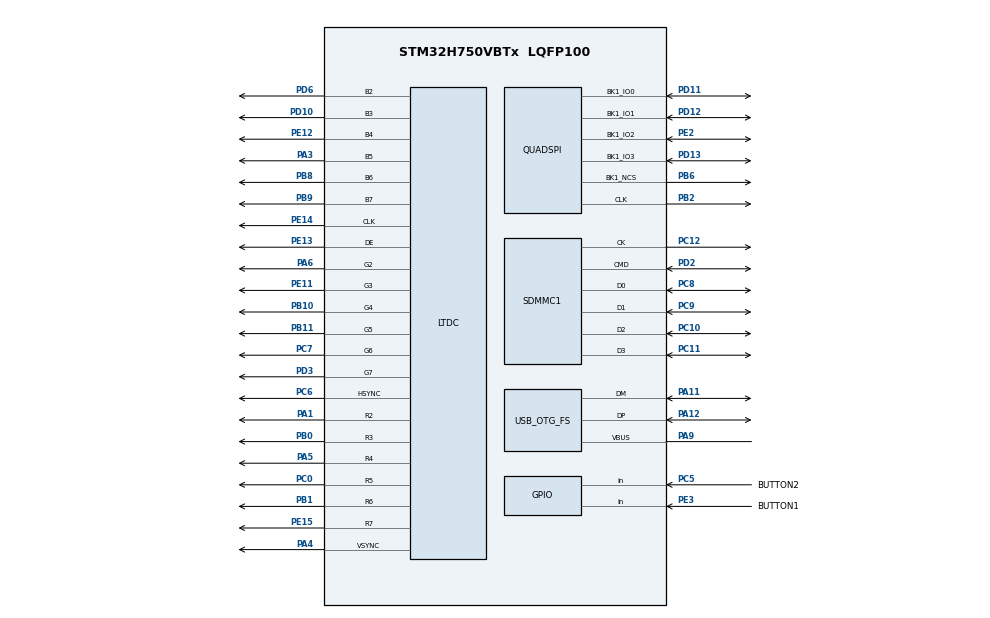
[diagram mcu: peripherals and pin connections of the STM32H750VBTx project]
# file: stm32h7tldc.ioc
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CORTEX_M7.AccessPermission-Cortex_Memory_Protection_Unit_Region0_Settings=MPU_REGION_FULL_ACCESS
CORTEX_M7.BaseAddress-Cortex_Memory_Protection_Unit_Region0_Settings=0x90000000
CORTEX_M7.CPU_DCache=Disabled
CORTEX_M7.CPU_ICache=Enabled
CORTEX_M7.DisableExec-Cortex_Memory_Protection_Unit_Region0_Settings=MPU_INSTRUCTION_ACCESS_DISABLE
CORTEX_M7.Enable-Cortex_Memory_Protection_Unit_Region0_Settings=MPU_REGION_ENABLE
CORTEX_M7.IsBufferable-Cortex_Memory_Protection_Unit_Region0_Settings=MPU_ACCESS_BUFFERABLE
CORTEX_M7.IsCacheable-Cortex_Memory_Protection_Unit_Region0_Settings=MPU_ACCESS_CACHEABLE
CORTEX_M7.MPU_Control=MPU_HFNMI_PRIVDEF
CORTEX_M7.Size-Cortex_Memory_Protection_Unit_Region0_Settings=MPU_REGION_SIZE_8MB
FATFS._FS_EXFAT=1
FATFS._FS_MINIMIZE=1
FATFS._LFN_UNICODE=1
FATFS._STRF_ENCODE=0
FATFS._USE_LFN=1
FATFS._USE_MKFS=0
JPEG.USE_JPEG_DECODER=0
JPEG.USE_JPEG_ENCODER=1
LTDC.ActiveH=480
LTDC.ActiveW=848
LTDC.Alpha0_L0=0xff
LTDC.Alpha_L0=0xff
LTDC.BlendingFactor2_L0=LTDC_BLENDING_FACTOR2_PAxCA
LTDC.Blue_L0=0
LTDC.DEPolarity=LTDC_DEPOLARITY_AL
LTDC.FBStartAdress_L0=(uint32_t)VideoRam
LTDC.Green_L0=0xff
LTDC.HBP=112
LTDC.HFP=16
LTDC.HSPolarity=LTDC_HSPOLARITY_AH
LTDC.HSync=112
LTDC.ImageHeight_L0=480
LTDC.ImageWidth_L0=848
LTDC.Layers=0
LTDC.PCPolarity=LTDC_PCPOLARITY_IIPC
LTDC.PixelFormat_L0=LTDC_PIXEL_FORMAT_L8
LTDC.Red_L0=0
LTDC.VBP=23
LTDC.VFP=6
LTDC.VSPolarity=LTDC_VSPOLARITY_AH
LTDC.VSync=8
LTDC.WindowX1_L0=847
LTDC.WindowY1_L0=479
Mcu.Family=STM32H7
Mcu.Name=STM32H750VBTx
Mcu.Package=LQFP100
Mdma.MDMA_Channel0.JPEG_INFIFO_TH.0.BlockCount=0
Mdma.MDMA_Channel0.JPEG_INFIFO_TH.0.BlockDataLength=0
Mdma.MDMA_Channel0.JPEG_INFIFO_TH.0.BufferTransferLength=32
Mdma.MDMA_Channel0.JPEG_INFIFO_TH.0.CircularMode=MDMA_LINEAR_LIST
Mdma.MDMA_Channel0.JPEG_INFIFO_TH.0.DataAlignment=MDMA_DATAALIGN_PACKENABLE
Mdma.MDMA_Channel0.JPEG_INFIFO_TH.0.DestBlockAddressOffset=0
Mdma.MDMA_Channel0.JPEG_INFIFO_TH.0.DestBurst=MDMA_DEST_BURST_16BEATS
Mdma.MDMA_Channel0.JPEG_INFIFO_TH.0.DestDataSize=MDMA_DEST_DATASIZE_WORD
Mdma.MDMA_Channel0.JPEG_INFIFO_TH.0.DestinationInc=MDMA_DEST_INC_DISABLE
Mdma.MDMA_Channel0.JPEG_INFIFO_TH.0.DstAddress=0
Mdma.MDMA_Channel0.JPEG_INFIFO_TH.0.Endianness=MDMA_LITTLE_ENDIANNESS_PRESERVE
Mdma.MDMA_Channel0.JPEG_INFIFO_TH.0.Instance=MDMA_Channel0
Mdma.MDMA_Channel0.JPEG_INFIFO_TH.0.MaskAddress=0
Mdma.MDMA_Channel0.JPEG_INFIFO_TH.0.MaskData=0
Mdma.MDMA_Channel0.JPEG_INFIFO_TH.0.Priority=MDMA_PRIORITY_HIGH
Mdma.MDMA_Channel0.JPEG_INFIFO_TH.0.Rank=First
Mdma.MDMA_Channel0.JPEG_INFIFO_TH.0.SourceBlockAddressOffset=0
Mdma.MDMA_Channel0.JPEG_INFIFO_TH.0.SourceBurst=MDMA_SOURCE_BURST_32BEATS
Mdma.MDMA_Channel0.JPEG_INFIFO_TH.0.SourceDataSize=MDMA_SRC_DATASIZE_BYTE
Mdma.MDMA_Channel0.JPEG_INFIFO_TH.0.SourceInc=MDMA_SRC_INC_BYTE
Mdma.MDMA_Channel0.JPEG_INFIFO_TH.0.SrcAddress=0
Mdma.MDMA_Channel0.JPEG_INFIFO_TH.0.TransferTriggerMode=MDMA_BUFFER_TRANSFER
Mdma.MDMA_Channel0.Request0=JPEG_INFIFO_TH
Mdma.MDMA_Channel0.RequestsNb=1
Mdma.MDMA_Channel1.JPEG_OUTFIFO_TH.0.BlockCount=0
Mdma.MDMA_Channel1.JPEG_OUTFIFO_TH.0.BlockDataLength=0
Mdma.MDMA_Channel1.JPEG_OUTFIFO_TH.0.BufferTransferLength=32
Mdma.MDMA_Channel1.JPEG_OUTFIFO_TH.0.CircularMode=MDMA_LINEAR_LIST
Mdma.MDMA_Channel1.JPEG_OUTFIFO_TH.0.DataAlignment=MDMA_DATAALIGN_PACKENABLE
Mdma.MDMA_Channel1.JPEG_OUTFIFO_TH.0.DestBlockAddressOffset=0
Mdma.MDMA_Channel1.JPEG_OUTFIFO_TH.0.DestBurst=MDMA_DEST_BURST_32BEATS
Mdma.MDMA_Channel1.JPEG_OUTFIFO_TH.0.DestDataSize=MDMA_DEST_DATASIZE_BYTE
Mdma.MDMA_Channel1.JPEG_OUTFIFO_TH.0.DestinationInc=MDMA_DEST_INC_BYTE
Mdma.MDMA_Channel1.JPEG_OUTFIFO_TH.0.DstAddress=0
Mdma.MDMA_Channel1.JPEG_OUTFIFO_TH.0.Endianness=MDMA_LITTLE_ENDIANNESS_PRESERVE
Mdma.MDMA_Channel1.JPEG_OUTFIFO_TH.0.Instance=MDMA_Channel1
Mdma.MDMA_Channel1.JPEG_OUTFIFO_TH.0.MaskAddress=0
Mdma.MDMA_Channel1.JPEG_OUTFIFO_TH.0.MaskData=0
Mdma.MDMA_Channel1.JPEG_OUTFIFO_TH.0.Priority=MDMA_PRIORITY_VERY_HIGH
Mdma.MDMA_Channel1.JPEG_OUTFIFO_TH.0.Rank=First
Mdma.MDMA_Channel1.JPEG_OUTFIFO_TH.0.SourceBlockAddressOffset=0
Mdma.MDMA_Channel1.JPEG_OUTFIFO_TH.0.SourceBurst=MDMA_SOURCE_BURST_32BEATS
Mdma.MDMA_Channel1.JPEG_OUTFIFO_TH.0.SourceDataSize=MDMA_SRC_DATASIZE_WORD
Mdma.MDMA_Channel1.JPEG_OUTFIFO_TH.0.SourceInc=MDMA_SRC_INC_DISABLE
Mdma.MDMA_Channel1.JPEG_OUTFIFO_TH.0.SrcAddress=0
Mdma.MDMA_Channel1.JPEG_OUTFIFO_TH.0.TransferTriggerMode=MDMA_BUFFER_TRANSFER
Mdma.MDMA_Channel1.Request0=JPEG_OUTFIFO_TH
Mdma.MDMA_Channel1.RequestsNb=1
Mdma.RequestSet0=MDMA_Channel0
Mdma.RequestSet1=MDMA_Channel1
Mdma.RequestSetsNb=2
NVIC.JPEG_IRQn=true\:0\:0\:false\:false\:true\:true\:true\:true
NVIC.MDMA_IRQn=true\:0\:0\:false\:false\:true\:false\:true\:true
NVIC.OTG_FS_IRQn=true\:0\:0\:false\:false\:true\:false\:true\:true
NVIC.PriorityGroup=NVIC_PRIORITYGROUP_4
PA1.Mode=RGB666
PA1.Signal=LTDC_R2
PA11.Mode=Host_Only
PA11.Signal=USB_OTG_FS_DM
PA12.Mode=Host_Only
PA12.Signal=USB_OTG_FS_DP
PA3.GPIO_Speed=GPIO_SPEED_FREQ_VERY_HIGH
PA3.Mode=RGB666
PA3.Signal=LTDC_B5
PA4.GPIO_Speed=GPIO_SPEED_FREQ_VERY_HIGH
PA4.Mode=RGB666
PA4.Signal=LTDC_VSYNC
PA5.GPIO_Speed=GPIO_SPEED_FREQ_VERY_HIGH
PA5.Mode=RGB666
PA5.Signal=LTDC_R4
PA6.GPIO_Speed=GPIO_SPEED_FREQ_VERY_HIGH
PA6.Mode=RGB666
PA6.Signal=LTDC_G2
PA9.Mode=Activate_VBUS
PA9.Signal=USB_OTG_FS_VBUS
PB0.GPIO_Speed=GPIO_SPEED_FREQ_VERY_HIGH
PB0.Mode=RGB666
PB0.Signal=LTDC_R3
PB1.GPIO_Speed=GPIO_SPEED_FREQ_VERY_HIGH
PB1.Mode=RGB666
PB1.Signal=LTDC_R6
PB10.GPIO_Speed=GPIO_SPEED_FREQ_VERY_HIGH
PB10.Mode=RGB666
PB10.Signal=LTDC_G4
PB11.GPIO_Speed=GPIO_SPEED_FREQ_VERY_HIGH
PB11.Mode=RGB666
PB11.Signal=LTDC_G5
PB2.GPIO_Speed=GPIO_SPEED_FREQ_VERY_HIGH
PB2.Mode=Single Bank 1
PB2.Signal=QUADSPI_CLK
PB6.GPIO_Speed=GPIO_SPEED_FREQ_VERY_HIGH
PB6.Mode=Single Bank 1
PB6.Signal=QUADSPI_BK1_NCS
PB8.GPIO_Speed=GPIO_SPEED_FREQ_VERY_HIGH
PB8.Mode=RGB666
PB8.Signal=LTDC_B6
PB9.GPIO_Speed=GPIO_SPEED_FREQ_VERY_HIGH
PB9.Mode=RGB666
PB9.Signal=LTDC_B7
PC0.GPIO_Speed=GPIO_SPEED_FREQ_VERY_HIGH
PC0.Mode=RGB666
PC0.Signal=LTDC_R5
PC10.Mode=SD_4_bits_Wide_bus
PC10.Signal=SDMMC1_D2
PC11.Mode=SD_4_bits_Wide_bus
PC11.Signal=SDMMC1_D3
PC12.Mode=SD_4_bits_Wide_bus
PC12.Signal=SDMMC1_CK
PC14-OSC32_IN\ (OSC32_IN).Mode=LSE-External-Oscillator
PC14-OSC32_IN\ (OSC32_IN).Signal=RCC_OSC32_IN
PC15-OSC32_OUT\ (OSC32_OUT).Mode=LSE-External-Oscillator
PC15-OSC32_OUT\ (OSC32_OUT).Signal=RCC_OSC32_OUT
PC5.GPIO_Label=BUTTON2
PC5.GPIO_PuPd=GPIO_PULLUP
PC5.Signal=GPIO_Input
PC6.GPIO_Speed=GPIO_SPEED_FREQ_VERY_HIGH
PC6.Mode=RGB666
PC6.Signal=LTDC_HSYNC
PC7.GPIO_Speed=GPIO_SPEED_FREQ_VERY_HIGH
PC7.Mode=RGB666
PC7.Signal=LTDC_G6
PC8.Mode=SD_4_bits_Wide_bus
PC8.Signal=SDMMC1_D0
PC9.Mode=SD_4_bits_Wide_bus
PC9.Signal=SDMMC1_D1
PD10.GPIO_Speed=GPIO_SPEED_FREQ_VERY_HIGH
PD10.Mode=RGB666
PD10.Signal=LTDC_B3
PD11.GPIO_Speed=GPIO_SPEED_FREQ_VERY_HIGH
PD11.Mode=Single Bank 1
PD11.Signal=QUADSPI_BK1_IO0
PD12.GPIO_Speed=GPIO_SPEED_FREQ_VERY_HIGH
PD12.Mode=Single Bank 1
PD12.Signal=QUADSPI_BK1_IO1
PD13.GPIO_Speed=GPIO_SPEED_FREQ_VERY_HIGH
PD13.Mode=Single Bank 1
PD13.Signal=QUADSPI_BK1_IO3
PD2.Mode=SD_4_bits_Wide_bus
PD2.Signal=SDMMC1_CMD
PD3.GPIO_Speed=GPIO_SPEED_FREQ_VERY_HIGH
PD3.Mode=RGB666
PD3.Signal=LTDC_G7
PD6.Mode=RGB666
PD6.Signal=LTDC_B2
PE11.GPIO_Speed=GPIO_SPEED_FREQ_VERY_HIGH
PE11.Mode=RGB666
PE11.Signal=LTDC_G3
PE12.GPIO_Speed=GPIO_SPEED_FREQ_VERY_HIGH
PE12.Mode=RGB666
PE12.Signal=LTDC_B4
PE13.GPIO_Speed=GPIO_SPEED_FREQ_VERY_HIGH
PE13.Mode=RGB666
PE13.Signal=LTDC_DE
PE14.GPIO_Speed=GPIO_SPEED_FREQ_VERY_HIGH
PE14.Mode=RGB666
PE14.Signal=LTDC_CLK
PE15.GPIO_Speed=GPIO_SPEED_FREQ_VERY_HIGH
PE15.Mode=RGB666
PE15.Signal=LTDC_R7
PE2.GPIO_Speed=GPIO_SPEED_FREQ_VERY_HIGH
PE2.Mode=Single Bank 1
PE2.Signal=QUADSPI_BK1_IO2
PE3.GPIO_Label=BUTTON1
PE3.GPIO_PuPd=GPIO_PULLUP
PE3.Signal=GPIO_Input
PH0-OSC_IN\ (PH0).Mode=HSE-External-Oscillator
PH0-OSC_IN\ (PH0).Signal=RCC_OSC_IN
PH1-OSC_OUT\ (PH1).Mode=HSE-External-Oscillator
PH1-OSC_OUT\ (PH1).Signal=RCC_OSC_OUT
ProjectManager.HeapSize=0x200
ProjectManager.StackSize=0x400
ProjectManager.TargetToolchain=STM32CubeIDE
QUADSPI.ChipSelectHighTime=QSPI_CS_HIGH_TIME_8_CYCLE
QUADSPI.ClockMode=QSPI_CLOCK_MODE_3
QUADSPI.ClockPrescaler=1
QUADSPI.DeviceType=SPI_DEVICE_FLASH
QUADSPI.FifoThreshold=32
QUADSPI.FlashSize=22
QUADSPI.SampleShifting=QSPI_SAMPLE_SHIFTING_HALFCYCLE
RCC.ADCFreq_Value=80000000
RCC.APB1Freq_Value=120000000
RCC.APB2Freq_Value=120000000
RCC.APB3Freq_Value=120000000
RCC.APB4Freq_Value=120000000
RCC.CKPERSourceSelection=RCC_CLKPSOURCE_HSE
RCC.CortexFreq_Value=480000000
RCC.D1PPRE=RCC_APB3_DIV2
RCC.D2PPRE1=RCC_APB1_DIV2
RCC.D2PPRE2=RCC_APB2_DIV2
RCC.D3PPRE=RCC_APB4_DIV2
RCC.DIVM1=5
RCC.DIVM2=5
RCC.DIVM3=10
RCC.DIVN1=192
RCC.DIVN2=80
RCC.DIVN3=297
RCC.DIVP2=5
RCC.DIVQ1=8
RCC.DIVQ2=1
RCC.DIVR3=5
RCC.HCLKFreq_Value=240000000
RCC.HPRE=RCC_HCLK_DIV2
RCC.HSE_VALUE=25000000
RCC.PLLFRACN=0
RCC.PLLSourceVirtual=RCC_PLLSOURCE_HSE
RCC.PWR_Regulator_Voltage_Scale=PWR_REGULATOR_VOLTAGE_SCALE0
RCC.QSPICLockSelection=RCC_QSPICLKSOURCE_PLL2
RCC.RTCClockSelection=RCC_RTCCLKSOURCE_LSE
RCC.SDMMC1CLockSelection=RCC_SDMMCCLKSOURCE_PLL2
RCC.SPI123CLockSelection=RCC_SPI123CLKSOURCE_PLL2
RCC.SYSCLKFreq_VALUE=480000000
RCC.SYSCLKSource=RCC_SYSCLKSOURCE_PLLCLK
RCC.Spi45ClockSelection=RCC_SPI45CLKSOURCE_PLL3
RCC.USBCLockSelection=RCC_USBCLKSOURCE_HSI48
RCC.USBFreq_Value=48000000
RTC.Hours=12
RTC.Month=RTC_MONTH_JUNE
RTC.Year=20
SDMMC1.ClockDiv=5
USB_HOST.USBH_HandleTypeDef-HID_FS=hUsbHostFS
USB_HOST.VirtualModeFS=Hid
USB_OTG_FS.VirtualMode=Host_Only
USB_OTG_FS.phy_itface=HCD_PHY_EMBEDDED
VP_FATFS_VS_Generic.Mode=User_defined
VP_FATFS_VS_SDIO.Mode=SDIO
VP_JPEG_VS_JPEG.Mode=JPEG_Activate
VP_MEMORYMAP_VS_MEMORYMAP.Mode=CurAppReg
VP_RTC_VS_RTC_Activate.Mode=RTC_Enabled
VP_RTC_VS_RTC_Calendar.Mode=RTC_Calendar
VP_USB_HOST_VS_USB_HOST_HID_FS.Mode=HID_FS
board=custom

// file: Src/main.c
/* USER CODE BEGIN Header */
/**
  ******************************************************************************
  * @file           : main.c
  * @brief          : Main program body
  ******************************************************************************
  * @attention
  *
  * Copyright (c) 2024 STMicroelectronics.
  * All rights reserved.
  *
  * This software is licensed under terms that can be found in the LICENSE file
  * in the root directory of this software component.
  * If no LICENSE file comes with this software, it is provided AS-IS.
  *
  ******************************************************************************
  */
/* USER CODE END Header */
#include "main.h"
#include "fatfs.h"
#include "jpeg.h"
#include "mdma.h"
#include "memorymap.h"
#include "rtc.h"
#include "sdmmc.h"
#include "usb_host.h"
#include "gpio.h"

/* USER CODE BEGIN Includes */
#include "startup.h"
/* USER CODE END Includes */

void SystemClock_Config(void);
void PeriphCommonClock_Config(void);
static void MPU_Config(void);
void MX_USB_HOST_Process(void);

int main(void)
{

  /* MPU Configuration--------------------------------------------------------*/
  MPU_Config();

  /* Enable the CPU Cache */

  /* Enable I-Cache---------------------------------------------------------*/
  SCB_EnableICache();

  /* MCU Configuration--------------------------------------------------------*/

  /* Reset of all peripherals, Initializes the Flash interface and the Systick. */
  HAL_Init();

  /* Configure the system clock */
  SystemClock_Config();

  /* Configure the peripherals common clocks */
  PeriphCommonClock_Config();

  /* USER CODE BEGIN SysInit */
  initialize();
  /* USER CODE END SysInit */

  /* Initialize all configured peripherals */
  MX_GPIO_Init();
  MX_MDMA_Init();
  MX_RTC_Init();
  MX_SDMMC1_SD_Init();
  MX_FATFS_Init();
  MX_JPEG_Init();
  MX_USB_HOST_Init();
  /* USER CODE BEGIN 2 */
  setup();
  /* USER CODE END 2 */

  /* Infinite loop */
  while (1)
  {
    MX_USB_HOST_Process();

    /* USER CODE BEGIN 3 */
	loop();
  }
  /* USER CODE END 3 */
}

void SystemClock_Config(void)
{
  RCC_OscInitTypeDef RCC_OscInitStruct = {0};
  RCC_ClkInitTypeDef RCC_ClkInitStruct = {0};

  /** Supply configuration update enable
  */
  HAL_PWREx_ConfigSupply(PWR_LDO_SUPPLY);

  /** Configure the main internal regulator output voltage
  */
  __HAL_PWR_VOLTAGESCALING_CONFIG(PWR_REGULATOR_VOLTAGE_SCALE0);

  while(!__HAL_PWR_GET_FLAG(PWR_FLAG_VOSRDY)) {}

  /** Configure LSE Drive Capability
  */
  HAL_PWR_EnableBkUpAccess();
  __HAL_RCC_LSEDRIVE_CONFIG(RCC_LSEDRIVE_LOW);

  /** Initializes the RCC Oscillators according to the specified parameters
  * in the RCC_OscInitTypeDef structure.
  */
  RCC_OscInitStruct.OscillatorType = RCC_OSCILLATORTYPE_HSI48|RCC_OSCILLATORTYPE_HSE
                              |RCC_OSCILLATORTYPE_LSE;
  RCC_OscInitStruct.HSEState = RCC_HSE_ON;
  RCC_OscInitStruct.LSEState = RCC_LSE_ON;
  RCC_OscInitStruct.HSI48State = RCC_HSI48_ON;
  RCC_OscInitStruct.PLL.PLLState = RCC_PLL_ON;
  RCC_OscInitStruct.PLL.PLLSource = RCC_PLLSOURCE_HSE;
  RCC_OscInitStruct.PLL.PLLM = 5;
  RCC_OscInitStruct.PLL.PLLN = 192;
  RCC_OscInitStruct.PLL.PLLP = 2;
  RCC_OscInitStruct.PLL.PLLQ = 8;
  RCC_OscInitStruct.PLL.PLLR = 2;
  RCC_OscInitStruct.PLL.PLLRGE = RCC_PLL1VCIRANGE_2;
  RCC_OscInitStruct.PLL.PLLVCOSEL = RCC_PLL1VCOWIDE;
  RCC_OscInitStruct.PLL.PLLFRACN = 0;
  if (HAL_RCC_OscConfig(&RCC_OscInitStruct) != HAL_OK)
  {
    Error_Handler();
  }

  /** Initializes the CPU, AHB and APB buses clocks
  */
  RCC_ClkInitStruct.ClockType = RCC_CLOCKTYPE_HCLK|RCC_CLOCKTYPE_SYSCLK
                              |RCC_CLOCKTYPE_PCLK1|RCC_CLOCKTYPE_PCLK2
                              |RCC_CLOCKTYPE_D3PCLK1|RCC_CLOCKTYPE_D1PCLK1;
  RCC_ClkInitStruct.SYSCLKSource = RCC_SYSCLKSOURCE_PLLCLK;
  RCC_ClkInitStruct.SYSCLKDivider = RCC_SYSCLK_DIV1;
  RCC_ClkInitStruct.AHBCLKDivider = RCC_HCLK_DIV2;
  RCC_ClkInitStruct.APB3CLKDivider = RCC_APB3_DIV2;
  RCC_ClkInitStruct.APB1CLKDivider = RCC_APB1_DIV2;
  RCC_ClkInitStruct.APB2CLKDivider = RCC_APB2_DIV2;
  RCC_ClkInitStruct.APB4CLKDivider = RCC_APB4_DIV2;

  if (HAL_RCC_ClockConfig(&RCC_ClkInitStruct, FLASH_LATENCY_4) != HAL_OK)
  {
    Error_Handler();
  }
}

void PeriphCommonClock_Config(void)
{
  RCC_PeriphCLKInitTypeDef PeriphClkInitStruct = {0};

  /** Initializes the peripherals clock
  */
  PeriphClkInitStruct.PeriphClockSelection = RCC_PERIPHCLK_QSPI|RCC_PERIPHCLK_SDMMC;
  PeriphClkInitStruct.PLL2.PLL2M = 5;
  PeriphClkInitStruct.PLL2.PLL2N = 80;
  PeriphClkInitStruct.PLL2.PLL2P = 5;
  PeriphClkInitStruct.PLL2.PLL2Q = 1;
  PeriphClkInitStruct.PLL2.PLL2R = 2;
  PeriphClkInitStruct.PLL2.PLL2RGE = RCC_PLL2VCIRANGE_2;
  PeriphClkInitStruct.PLL2.PLL2VCOSEL = RCC_PLL2VCOWIDE;
  PeriphClkInitStruct.PLL2.PLL2FRACN = 0;
  PeriphClkInitStruct.QspiClockSelection = RCC_QSPICLKSOURCE_PLL2;
  PeriphClkInitStruct.SdmmcClockSelection = RCC_SDMMCCLKSOURCE_PLL2;
  if (HAL_RCCEx_PeriphCLKConfig(&PeriphClkInitStruct) != HAL_OK)
  {
    Error_Handler();
  }
}

 /* MPU Configuration */

void MPU_Config(void)
{
  MPU_Region_InitTypeDef MPU_InitStruct = {0};

  /* Disables the MPU */
  HAL_MPU_Disable();

  /** Initializes and configures the Region and the memory to be protected
  */
  MPU_InitStruct.Enable = MPU_REGION_ENABLE;
  MPU_InitStruct.Number = MPU_REGION_NUMBER0;
  MPU_InitStruct.BaseAddress = 0x90000000;
  MPU_InitStruct.Size = MPU_REGION_SIZE_8MB;
  MPU_InitStruct.SubRegionDisable = 0x0;
  MPU_InitStruct.TypeExtField = MPU_TEX_LEVEL0;
  MPU_InitStruct.AccessPermission = MPU_REGION_FULL_ACCESS;
  MPU_InitStruct.DisableExec = MPU_INSTRUCTION_ACCESS_DISABLE;
  MPU_InitStruct.IsShareable = MPU_ACCESS_NOT_SHAREABLE;
  MPU_InitStruct.IsCacheable = MPU_ACCESS_CACHEABLE;
  MPU_InitStruct.IsBufferable = MPU_ACCESS_BUFFERABLE;

  HAL_MPU_ConfigRegion(&MPU_InitStruct);
  /* Enables the MPU */
  HAL_MPU_Enable(MPU_HFNMI_PRIVDEF);

}

void Error_Handler(void)
{
  __disable_irq();
  while (1)
  {
  }
}
